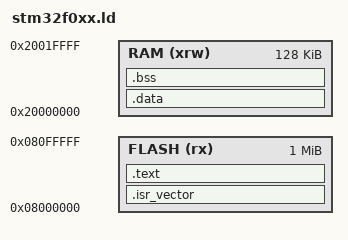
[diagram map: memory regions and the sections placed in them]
/* Example for STM32F407VG */
ENTRY(Reset_Handler)

MEMORY
{
    FLASH (rx)  : ORIGIN = 0x08000000, LENGTH = 1024K
    RAM (xrw)   : ORIGIN = 0x20000000, LENGTH = 128K
}

_estack = ORIGIN(RAM) + LENGTH(RAM);

SECTIONS
{
    .isr_vector :
    {
        KEEP(*(.isr_vector))
    } > FLASH

    .text :
    {
        *(.text*)
        *(.rodata*)
        _etext = .;
    } > FLASH

    _sidata = LOADADDR(.data);

    .data : AT(_etext)
    {
        _sdata = .;
        *(.data*)
        _edata = .;
    } > RAM

    .bss :
    {
        _sbss = .;
        *(.bss*)
        *(COMMON)
        _ebss = .;
    } > RAM
}
